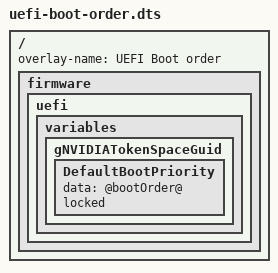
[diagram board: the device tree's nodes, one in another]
/dts-v1/;
/plugin/;

/ {
	overlay-name = "UEFI Boot order";

	fragment@0 {
		target-path = "/";
		board_config {
			sw-modules = "uefi";
		};

		__overlay__ {
			firmware {
				uefi {
					variables {
						gNVIDIATokenSpaceGuid {
							DefaultBootPriority {
								data = "@bootOrder@";
								locked;
							};
						};
					};
				};
			};
		};
	};
};
